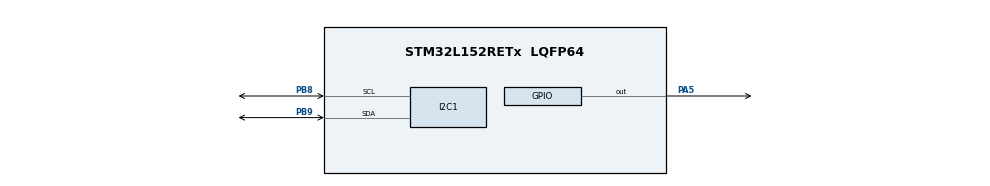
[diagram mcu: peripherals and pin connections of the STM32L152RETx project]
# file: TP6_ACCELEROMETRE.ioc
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Mcu.Family=STM32L1
Mcu.Name=STM32L152RETx
Mcu.Package=LQFP64
NVIC.PriorityGroup=NVIC_PRIORITYGROUP_4
PA5.Signal=GPIO_Output
PB8.Mode=I2C
PB8.Signal=I2C1_SCL
PB9.Mode=I2C
PB9.Signal=I2C1_SDA
ProjectManager.HeapSize=0x200
ProjectManager.StackSize=0x400
ProjectManager.TargetToolchain=STM32CubeIDE
RCC.AHBFreq_Value=2097000
RCC.APB1Freq_Value=2097000
RCC.APB2Freq_Value=2097000
RCC.HSE_VALUE=24000000
RCC.HSI_VALUE=16000000
RCC.LSE_VALUE=32768
RCC.MSI_VALUE=2097000
RCC.SYSCLKFreq_VALUE=2097000
RCC.VCOOutputFreq_Value=48000000
board=custom

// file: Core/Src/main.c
/* USER CODE BEGIN Header */
/**
  ******************************************************************************
  * @file           : main.c
  * @brief          : Main program body
  ******************************************************************************
  * @attention
  *
  * Copyright (c) 2025 STMicroelectronics.
  * All rights reserved.
  *
  * This software is licensed under terms that can be found in the LICENSE file
  * in the root directory of this software component.
  * If no LICENSE file comes with this software, it is provided AS-IS.
  *
  ******************************************************************************
  */
/* USER CODE END Header */
#include "main.h"

/* USER CODE BEGIN Includes */
#include <string.h>

/* USER CODE END Includes */

I2C_HandleTypeDef hi2c1;

void SystemClock_Config(void);
static void MX_GPIO_Init(void);
static void MX_I2C1_Init(void);

int main(void)
{

  /* MCU Configuration--------------------------------------------------------*/

  /* Reset of all peripherals, Initializes the Flash interface and the Systick. */
  HAL_Init();

  /* Configure the system clock */
  SystemClock_Config();

  /* Initialize all configured peripherals */
  MX_GPIO_Init();
  MX_I2C1_Init();
  /* USER CODE BEGIN 2 */

/* WHO_AM_I
  uint8_t adress[1] = {0x0F};
  uint8_t rData[1];
*/
  uint8_t adresse[1] = {0x10} ;
  uint8_t rData[1];
  uint8_t wData[1];
  wData[0] = (1<<7);
  uint8_t data[2];
  memcpy(data, adresse, 1);
  memcpy(data+1, wData, 1);

  HAL_I2C_Master_Transmit(&hi2c1, 0xD6, data, 2, 100);
  HAL_Delay(100);
  adresse[0] = 0x2D;

  /* USER CODE END 2 */

  /* Infinite loop */
  while (1)
  {

    /* USER CODE BEGIN 3 */
/* WHO_AM_I
	  HAL_I2C_Master_Transmit(&hi2c1, 0xD6, adress, 1, 100);
	  HAL_I2C_Master_Receive(&hi2c1, 0xD6, rData, 1, 100);
*/
	  HAL_I2C_Master_Transmit(&hi2c1, 0xD6, adresse, 1, 100);
	  HAL_I2C_Master_Receive(&hi2c1, 0xD6, rData, 1, 100);

	  if((rData[0]>=0) && (rData[0]<=128)){
		  GPIOA -> ODR |= (1<<5);
	  } else if((rData[0]>128) && (rData[0]<=255)){
		  GPIOA -> ODR &= ~(1<<5);
	  }

	  HAL_Delay(100);
  }
  /* USER CODE END 3 */
}

void SystemClock_Config(void)
{
  RCC_OscInitTypeDef RCC_OscInitStruct = {0};
  RCC_ClkInitTypeDef RCC_ClkInitStruct = {0};

  /** Configure the main internal regulator output voltage
  */
  __HAL_PWR_VOLTAGESCALING_CONFIG(PWR_REGULATOR_VOLTAGE_SCALE1);

  /** Initializes the RCC Oscillators according to the specified parameters
  * in the RCC_OscInitTypeDef structure.
  */
  RCC_OscInitStruct.OscillatorType = RCC_OSCILLATORTYPE_HSI;
  RCC_OscInitStruct.HSIState = RCC_HSI_ON;
  RCC_OscInitStruct.HSICalibrationValue = RCC_HSICALIBRATION_DEFAULT;
  RCC_OscInitStruct.PLL.PLLState = RCC_PLL_NONE;
  if (HAL_RCC_OscConfig(&RCC_OscInitStruct) != HAL_OK)
  {
    Error_Handler();
  }

  /** Initializes the CPU, AHB and APB buses clocks
  */
  RCC_ClkInitStruct.ClockType = RCC_CLOCKTYPE_HCLK|RCC_CLOCKTYPE_SYSCLK
                              |RCC_CLOCKTYPE_PCLK1|RCC_CLOCKTYPE_PCLK2;
  RCC_ClkInitStruct.SYSCLKSource = RCC_SYSCLKSOURCE_HSI;
  RCC_ClkInitStruct.AHBCLKDivider = RCC_SYSCLK_DIV1;
  RCC_ClkInitStruct.APB1CLKDivider = RCC_HCLK_DIV1;
  RCC_ClkInitStruct.APB2CLKDivider = RCC_HCLK_DIV1;

  if (HAL_RCC_ClockConfig(&RCC_ClkInitStruct, FLASH_LATENCY_0) != HAL_OK)
  {
    Error_Handler();
  }
}

static void MX_I2C1_Init(void)
{

  hi2c1.Instance = I2C1;
  hi2c1.Init.ClockSpeed = 100000;
  hi2c1.Init.DutyCycle = I2C_DUTYCYCLE_2;
  hi2c1.Init.OwnAddress1 = 0;
  hi2c1.Init.AddressingMode = I2C_ADDRESSINGMODE_7BIT;
  hi2c1.Init.DualAddressMode = I2C_DUALADDRESS_DISABLE;
  hi2c1.Init.OwnAddress2 = 0;
  hi2c1.Init.GeneralCallMode = I2C_GENERALCALL_DISABLE;
  hi2c1.Init.NoStretchMode = I2C_NOSTRETCH_DISABLE;
  if (HAL_I2C_Init(&hi2c1) != HAL_OK)
  {
    Error_Handler();
  }

}

static void MX_GPIO_Init(void)
{
  GPIO_InitTypeDef GPIO_InitStruct = {0};

  /* GPIO Ports Clock Enable */
  __HAL_RCC_GPIOA_CLK_ENABLE();
  __HAL_RCC_GPIOB_CLK_ENABLE();

  /*Configure GPIO pin Output Level */
  HAL_GPIO_WritePin(GPIOA, GPIO_PIN_5, GPIO_PIN_RESET);

  /*Configure GPIO pin : PA5 */
  GPIO_InitStruct.Pin = GPIO_PIN_5;
  GPIO_InitStruct.Mode = GPIO_MODE_OUTPUT_PP;
  GPIO_InitStruct.Pull = GPIO_NOPULL;
  GPIO_InitStruct.Speed = GPIO_SPEED_FREQ_LOW;
  HAL_GPIO_Init(GPIOA, &GPIO_InitStruct);

}

void Error_Handler(void)
{
  __disable_irq();
  while (1)
  {
  }
}
